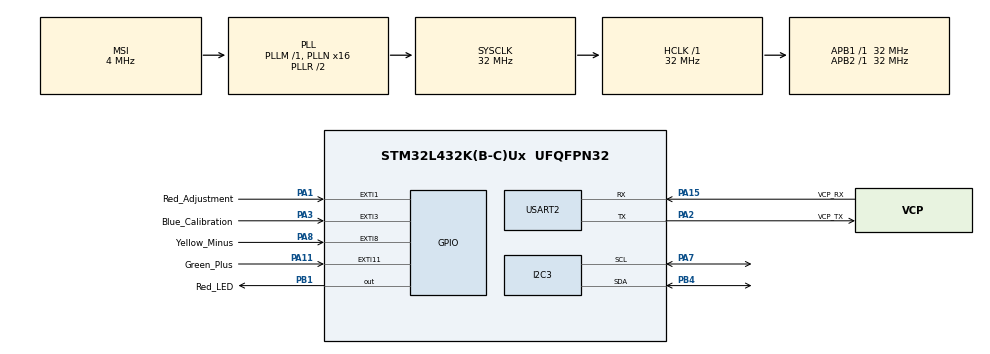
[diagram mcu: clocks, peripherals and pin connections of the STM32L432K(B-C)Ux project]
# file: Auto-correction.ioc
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I2C3.Timing=0x00B07CB4
Mcu.Family=STM32L4
Mcu.Name=STM32L432K(B-C)Ux
Mcu.Package=UFQFPN32
NVIC.EXTI15_10_IRQn=true\:0\:0\:false\:false\:true\:true\:true\:true
NVIC.EXTI1_IRQn=true\:0\:0\:false\:false\:true\:true\:true\:true
NVIC.EXTI3_IRQn=true\:0\:0\:false\:false\:true\:true\:true\:true
NVIC.EXTI9_5_IRQn=true\:0\:0\:false\:false\:true\:true\:true\:true
NVIC.PriorityGroup=NVIC_PRIORITYGROUP_4
NVIC.TIM1_BRK_TIM15_IRQn=true\:0\:0\:false\:false\:true\:true\:true\:true
NVIC.TIM2_IRQn=true\:1\:0\:true\:false\:true\:true\:true\:true
PA0.GPIO_Label=MCO [High speed clock in]
PA0.Mode=HSE-External-Clock-Source-for-LittleOrca
PA0.Signal=RCC_CK_IN
PA1.GPIO_Label=Red_Adjustment
PA1.GPIO_PuPd=GPIO_PULLDOWN
PA1.Signal=GPXTI1
PA11.GPIO_Label=Green_Plus
PA11.GPIO_PuPd=GPIO_PULLDOWN
PA11.Signal=GPXTI11
PA13\ (JTMS-SWDIO).GPIO_Label=SWDIO
PA13\ (JTMS-SWDIO).Mode=Serial_Wire
PA13\ (JTMS-SWDIO).Signal=SYS_JTMS-SWDIO
PA14\ (JTCK-SWCLK).GPIO_Label=SWCLK
PA14\ (JTCK-SWCLK).Mode=Serial_Wire
PA14\ (JTCK-SWCLK).Signal=SYS_JTCK-SWCLK
PA15\ (JTDI).GPIO_Label=VCP_RX
PA15\ (JTDI).Mode=Asynchronous
PA15\ (JTDI).Signal=USART2_RX
PA2.GPIO_Label=VCP_TX
PA2.Mode=Asynchronous
PA2.Signal=USART2_TX
PA3.GPIO_Label=Blue_Calibration
PA3.GPIO_PuPd=GPIO_PULLDOWN
PA3.Signal=GPXTI3
PA7.Mode=I2C
PA7.Signal=I2C3_SCL
PA8.GPIO_Label=Yellow_Minus
PA8.GPIO_PuPd=GPIO_PULLDOWN
PA8.Signal=GPXTI8
PB1.GPIO_Label=Red_LED
PB1.Signal=GPIO_Output
PB4\ (NJTRST).Mode=I2C
PB4\ (NJTRST).Signal=I2C3_SDA
PC14-OSC32_IN\ (PC14).Mode=LSE-External-Oscillator
PC14-OSC32_IN\ (PC14).Signal=RCC_OSC32_IN
PC15-OSC32_OUT\ (PC15).Mode=LSE-External-Oscillator
PC15-OSC32_OUT\ (PC15).Signal=RCC_OSC32_OUT
ProjectManager.HeapSize=0x200
ProjectManager.StackSize=0x400
ProjectManager.TargetToolchain=STM32CubeIDE
RCC.AHBFreq_Value=32000000
RCC.APB1Freq_Value=32000000
RCC.APB1TimFreq_Value=32000000
RCC.APB2Freq_Value=32000000
RCC.APB2TimFreq_Value=32000000
RCC.CortexFreq_Value=32000000
RCC.HCLKFreq_Value=32000000
RCC.HSE_VALUE=8000000
RCC.HSI16_VALUE=16000000
RCC.HSI48_VALUE=48000000
RCC.HSI_VALUE=16000000
RCC.MSI_VALUE=4000000
RCC.PLLMUL=RCC_PLLMUL_4
RCC.PLLN=16
RCC.SYSCLKFreq_VALUE=32000000
RCC.SYSCLKSource=RCC_SYSCLKSOURCE_PLLCLK
RCC.VCOOutputFreq_Value=64000000
TIM1.Period=1000-1
TIM1.Prescaler=640-1
TIM15.Period=1000-1
TIM15.Prescaler=3200-1
TIM2.Period=1000-1
TIM2.Prescaler=3200-1
USART2.VirtualMode-Asynchronous=VM_ASYNC
VP_CRC_VS_CRC.Mode=CRC_Activate
VP_TIM15_VS_ClockSourceINT.Mode=Internal
VP_TIM1_VS_ClockSourceINT.Mode=Internal
VP_TIM2_VS_ClockSourceINT.Mode=Internal
board=NUCLEO-L432KC

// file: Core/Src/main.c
/* USER CODE BEGIN Header */
/**
  ******************************************************************************
  * @file           : main.c
  * @brief          : Main program body
  ******************************************************************************
  * @attention
  *
  * Copyright (c) 2024 STMicroelectronics.
  * All rights reserved.
  *
  * This software is licensed under terms that can be found in the LICENSE file
  * in the root directory of this software component.
  * If no LICENSE file comes with this software, it is provided AS-IS.
  *
  ******************************************************************************
  */
/* USER CODE END Header */
#include "main.h"
#include "crc.h"
#include "i2c.h"
#include "tim.h"
#include "usart.h"
#include "gpio.h"

/* USER CODE BEGIN Includes */
#include "LCD_I2C.h"
#include "Clock.h"
#include "EEPROM.h"
#include "eeprom_emul_conf.h"
#include "eeprom_emul_types.h"
#include "eeprom_emul.h"
#include "flash_interface.h"
/* USER CODE END Includes */

void SystemClock_Config(void);

int main(void)
{

  /* MCU Configuration--------------------------------------------------------*/

  /* Reset of all peripherals, Initializes the Flash interface and the Systick. */
  HAL_Init();

  /* Configure the system clock */
  SystemClock_Config();

  /* Initialize all configured peripherals */
  MX_GPIO_Init();
  MX_USART2_UART_Init();
  MX_I2C3_Init();
  MX_TIM1_Init();
  MX_TIM2_Init();
  MX_TIM15_Init();
  MX_CRC_Init();
  /* USER CODE BEGIN 2 */
  set_time(24, 12, 5, 4, 19, 25, 0, 1); // Example: 17th November 2024, 10:00:00 AM
  LCD_Init();              // Initialize the LCD
  HAL_Delay(100);          // Wait for LCD to be ready
  __disable_irq();  // Disable all interrupts
  EEPROM_Init();
  __enable_irq();   // Re-enable all interrupts
  PPM_Init();
  HAL_TIM_Base_Start_IT(&htim2);
  /* USER CODE END 2 */

  /* Infinite loop */
  while (1)
  {

  }
}

void SystemClock_Config(void)
{
  RCC_OscInitTypeDef RCC_OscInitStruct = {0};
  RCC_ClkInitTypeDef RCC_ClkInitStruct = {0};

  /** Configure the main internal regulator output voltage
  */
  if (HAL_PWREx_ControlVoltageScaling(PWR_REGULATOR_VOLTAGE_SCALE1) != HAL_OK)
  {
    Error_Handler();
  }

  /** Configure LSE Drive Capability
  */
  HAL_PWR_EnableBkUpAccess();
  __HAL_RCC_LSEDRIVE_CONFIG(RCC_LSEDRIVE_LOW);

  /** Initializes the RCC Oscillators according to the specified parameters
  * in the RCC_OscInitTypeDef structure.
  */
  RCC_OscInitStruct.OscillatorType = RCC_OSCILLATORTYPE_LSE|RCC_OSCILLATORTYPE_MSI;
  RCC_OscInitStruct.LSEState = RCC_LSE_ON;
  RCC_OscInitStruct.MSIState = RCC_MSI_ON;
  RCC_OscInitStruct.MSICalibrationValue = 0;
  RCC_OscInitStruct.MSIClockRange = RCC_MSIRANGE_6;
  RCC_OscInitStruct.PLL.PLLState = RCC_PLL_ON;
  RCC_OscInitStruct.PLL.PLLSource = RCC_PLLSOURCE_MSI;
  RCC_OscInitStruct.PLL.PLLM = 1;
  RCC_OscInitStruct.PLL.PLLN = 16;
  RCC_OscInitStruct.PLL.PLLP = RCC_PLLP_DIV7;
  RCC_OscInitStruct.PLL.PLLQ = RCC_PLLQ_DIV2;
  RCC_OscInitStruct.PLL.PLLR = RCC_PLLR_DIV2;
  if (HAL_RCC_OscConfig(&RCC_OscInitStruct) != HAL_OK)
  {
    Error_Handler();
  }

  /** Initializes the CPU, AHB and APB buses clocks
  */
  RCC_ClkInitStruct.ClockType = RCC_CLOCKTYPE_HCLK|RCC_CLOCKTYPE_SYSCLK
                              |RCC_CLOCKTYPE_PCLK1|RCC_CLOCKTYPE_PCLK2;
  RCC_ClkInitStruct.SYSCLKSource = RCC_SYSCLKSOURCE_PLLCLK;
  RCC_ClkInitStruct.AHBCLKDivider = RCC_SYSCLK_DIV1;
  RCC_ClkInitStruct.APB1CLKDivider = RCC_HCLK_DIV1;
  RCC_ClkInitStruct.APB2CLKDivider = RCC_HCLK_DIV1;

  if (HAL_RCC_ClockConfig(&RCC_ClkInitStruct, FLASH_LATENCY_1) != HAL_OK)
  {
    Error_Handler();
  }

  /** Enable MSI Auto calibration
  */
  HAL_RCCEx_EnableMSIPLLMode();
}

void Error_Handler(void)
{
  __disable_irq();
  while (1)
  {
  }
}
